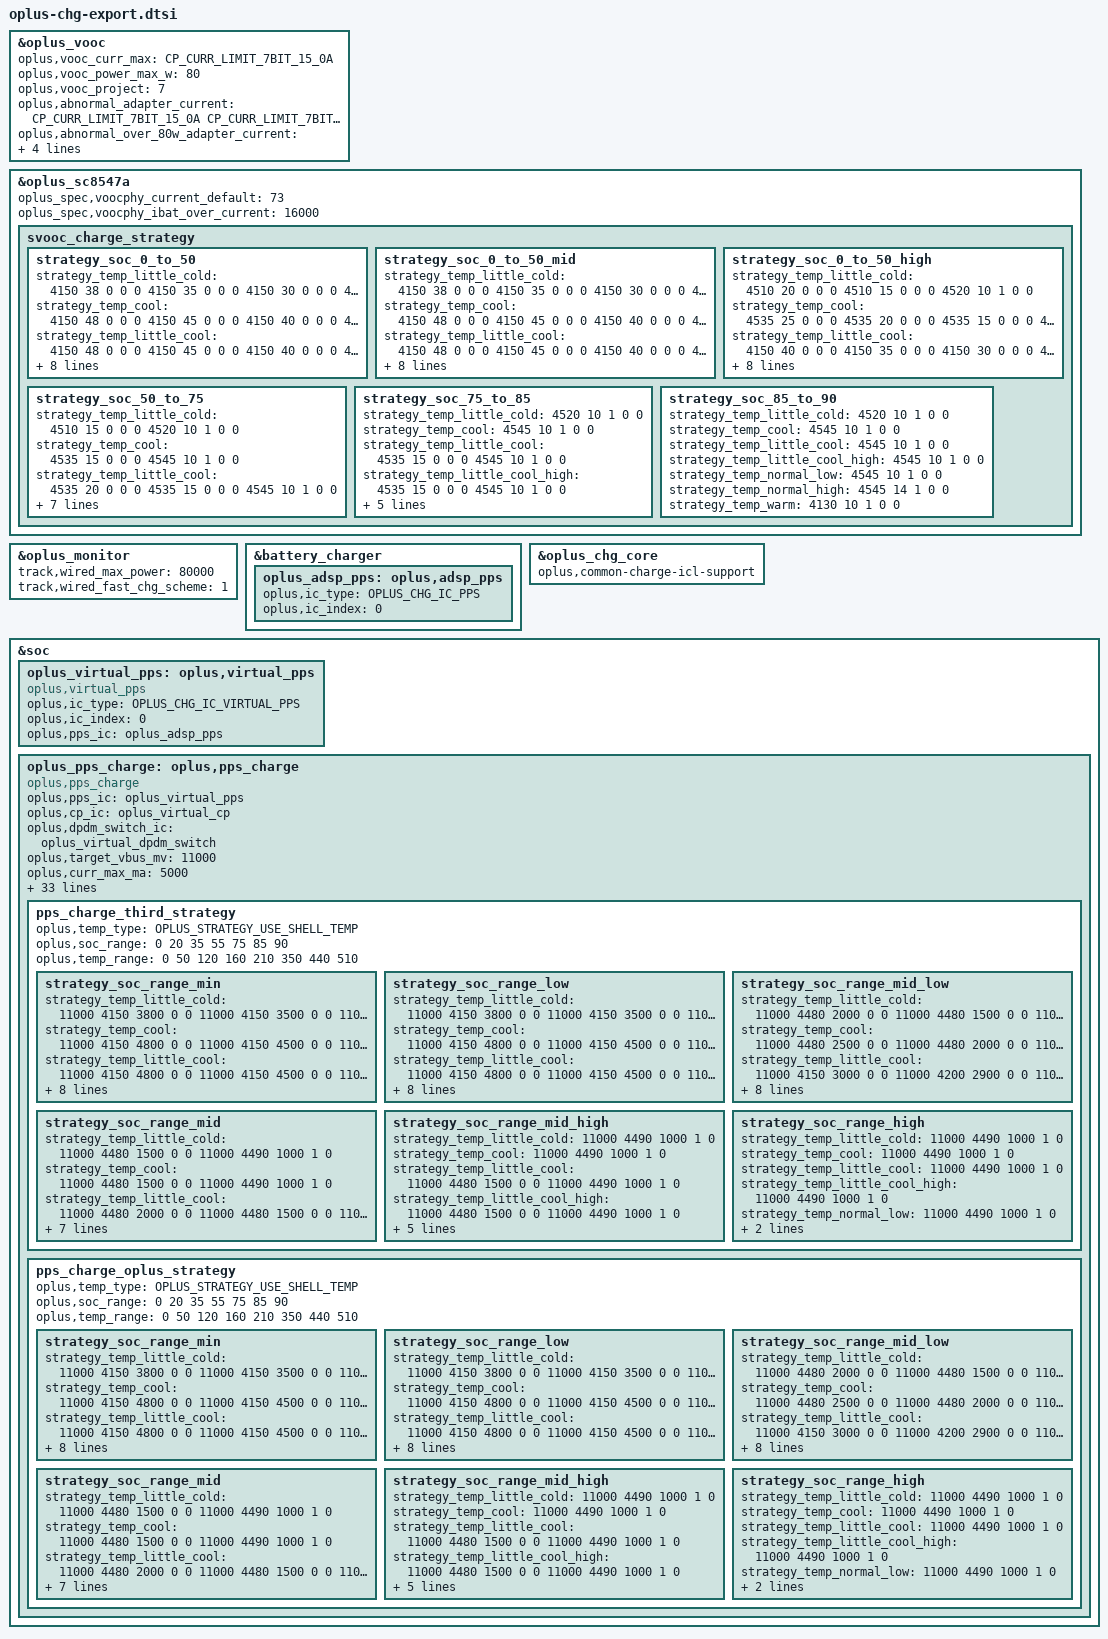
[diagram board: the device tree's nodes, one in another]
/* SVOOC */
&oplus_vooc {
	oplus,vooc_curr_max = <CP_CURR_LIMIT_7BIT_15_0A>;
	oplus,vooc_power_max_w = <80>;
	oplus,vooc_project = <7>;

	oplus,abnormal_adapter_current = <CP_CURR_LIMIT_7BIT_15_0A CP_CURR_LIMIT_7BIT_15_0A
					CP_CURR_LIMIT_7BIT_10_0A CP_CURR_LIMIT_7BIT_10_0A
					CP_CURR_LIMIT_7BIT_8_0A CP_CURR_LIMIT_7BIT_8_0A
					CP_CURR_LIMIT_7BIT_6_0A CP_CURR_LIMIT_7BIT_6_0A
					CP_CURR_LIMIT_7BIT_4_0A CP_CURR_LIMIT_7BIT_4_0A>;

	oplus,abnormal_over_80w_adapter_current = <CP_CURR_LIMIT_7BIT_15_0A CP_CURR_LIMIT_7BIT_15_0A
					CP_CURR_LIMIT_7BIT_14_0A CP_CURR_LIMIT_7BIT_14_0A
					CP_CURR_LIMIT_7BIT_12_0A CP_CURR_LIMIT_7BIT_12_0A
					CP_CURR_LIMIT_7BIT_10_0A CP_CURR_LIMIT_7BIT_10_0A
					CP_CURR_LIMIT_7BIT_8_0A CP_CURR_LIMIT_7BIT_8_0A
					CP_CURR_LIMIT_7BIT_6_0A CP_CURR_LIMIT_7BIT_6_0A
					CP_CURR_LIMIT_7BIT_4_0A CP_CURR_LIMIT_7BIT_4_0A>;

	/* first data is strategy used temp type */
	oplus,general_strategy_name = "cgcl";
	oplus,general_strategy_data = < OPLUS_STRATEGY_USE_SHELL_TEMP
					0   385 CP_CURR_LIMIT_7BIT_15_0A 1 0
					375 395 CP_CURR_LIMIT_7BIT_12_6A 2 0
					385 420 CP_CURR_LIMIT_7BIT_8_0A 3 1
					410 440 CP_CURR_LIMIT_7BIT_6_0A 3 2 >;
};

&oplus_sc8547a {
	oplus_spec,voocphy_current_default = <73>;
	oplus_spec,voocphy_ibat_over_current = <16000>;
	svooc_charge_strategy {
		strategy_soc_0_to_50 { /* 0 ~ 20 */
			strategy_temp_little_cold =	<4150 38 0 0 0
							4150 35 0 0 0
							4150 30 0 0 0
							4510 26 0 0 0
							4510 25 0 0 0
							4510 20 0 0 0
							4510 15 0 0 0
							4520 10 1 0 0>;
			strategy_temp_cool =		<4150 48 0 0 0
							4150 45 0 0 0
							4150 40 0 0 0
							4150 35 0 0 0
							4150 30 0 0 0
							4200 29 0 0 0
							4535 25 0 0 0
							4535 20 0 0 0
							4535 15 0 0 0
							4545 10 1 0 0>;
			strategy_temp_little_cool =	<4150 48 0 0 0
							4150 45 0 0 0
							4150 40 0 0 0
							4150 35 0 0 0
							4150 30 0 0 0
							4200 29 0 0 0
							4535 25 0 0 0
							4535 20 0 0 0
							4535 15 0 0 0
							4545 10 1 0 0>;
			strategy_temp_little_cool_high = <4050 73 0 0 0
							4230 61 0 0 0
							4230 50 0 0 0
							4230 40 0 0 0
							4380 39 0 0 0
							4380 35 0 0 0
							4380 30 0 0 0
							4535 29 0 0 0
							4535 25 0 0 0
							4535 20 0 0 0
							4535 15 0 0 0
							4545 10 1 0 0>;
			strategy_temp_normal_low =	<4050 73 0 0 0
							4230 61 0 0 0
							4230 50 0 0 0
							4230 40 0 0 0
							4380 39 0 0 0
							4380 35 0 0 0
							4380 30 0 0 0
							4535 29 0 0 0
							4535 25 0 0 0
							4535 20 0 0 0
							4535 15 0 0 0
							4545 10 1 0 0>;
			strategy_temp_normal_high =	<4200 61 0 0 0
							4200 60 0 0 0
							4200 50 0 0 0
							4230 48 0 0 0
							4230 45 0 0 0
							4230 40 0 0 0
							4380 39 0 0 0
							4380 35 0 0 0
							4380 30 0 0 0
							4535 29 0 0 0
							4535 25 0 0 0
							4535 20 0 0 0
							4535 15 0 0 0
							4545 14 1 0 0>;
			strategy_temp_warm =		<4120 32 0 0 0
							4120 30 0 0 0
							4120 25 0 0 0
							4120 20 0 0 0
							4120 15 0 0 0
							4130 10 1 0 0>;
		};

		strategy_soc_0_to_50_mid { /* 21 ~ 35 */
			strategy_temp_little_cold =	<4150 38 0 0 0
							4150 35 0 0 0
							4150 30 0 0 0
							4510 26 0 0 0
							4510 25 0 0 0
							4510 20 0 0 0
							4510 15 0 0 0
							4520 10 1 0 0>;
			strategy_temp_cool =		<4150 48 0 0 0
							4150 45 0 0 0
							4150 40 0 0 0
							4150 35 0 0 0
							4150 30 0 0 0
							4200 29 0 0 0
							4535 25 0 0 0
							4535 20 0 0 0
							4535 15 0 0 0
							4545 10 1 0 0>;
			strategy_temp_little_cool =	<4150 48 0 0 0
							4150 45 0 0 0
							4150 40 0 0 0
							4150 35 0 0 0
							4150 30 0 0 0
							4200 29 0 0 0
							4535 25 0 0 0
							4535 20 0 0 0
							4535 15 0 0 0
							4545 10 1 0 0>;
			strategy_temp_little_cool_high = <4050 73 0 0 0
							4230 61 0 0 0
							4230 50 0 0 0
							4230 40 0 0 0
							4380 39 0 0 0
							4380 35 0 0 0
							4380 30 0 0 0
							4535 29 0 0 0
							4535 25 0 0 0
							4535 20 0 0 0
							4535 15 0 0 0
							4545 10 1 0 0>;
			strategy_temp_normal_low =	<4050 73 0 0 0
							4230 61 0 0 0
							4230 50 0 0 0
							4230 40 0 0 0
							4380 39 0 0 0
							4380 35 0 0 0
							4380 30 0 0 0
							4535 29 0 0 0
							4535 25 0 0 0
							4535 20 0 0 0
							4535 15 0 0 0
							4545 10 1 0 0>;
			strategy_temp_normal_high =	<4200 61 0 0 0
							4200 60 0 0 0
							4200 50 0 0 0
							4230 48 0 0 0
							4230 45 0 0 0
							4230 40 0 0 0
							4380 39 0 0 0
							4380 35 0 0 0
							4380 30 0 0 0
							4535 29 0 0 0
							4535 25 0 0 0
							4535 20 0 0 0
							4535 15 0 0 0
							4545 14 1 0 0>;
			strategy_temp_warm =		<4120 32 0 0 0
							4120 30 0 0 0
							4120 25 0 0 0
							4120 20 0 0 0
							4120 15 0 0 0
							4130 10 1 0 0>;
		};

		strategy_soc_0_to_50_high { /* 36 ~ 55 */
			strategy_temp_little_cold =	<4510 20 0 0 0
							4510 15 0 0 0
							4520 10 1 0 0>;
			strategy_temp_cool =		<4535 25 0 0 0
							4535 20 0 0 0
							4535 15 0 0 0
							4545 10 1 0 0>;
			strategy_temp_little_cool =	<4150 40 0 0 0
							4150 35 0 0 0
							4150 30 0 0 0
							4200 29 0 0 0
							4535 25 0 0 0
							4535 20 0 0 0
							4535 15 0 0 0
							4545 10 1 0 0>;
			strategy_temp_little_cool_high = <4230 40 0 0 0
							4380 39 0 0 0
							4380 35 0 0 0
							4380 30 0 0 0
							4535 29 0 0 0
							4535 25 0 0 0
							4535 20 0 0 0
							4535 15 0 0 0
							4545 10 1 0 0>;
			strategy_temp_normal_low =	<4230 61 0 0 0
							4230 50 0 0 0
							4230 40 0 0 0
							4380 39 0 0 0
							4380 35 0 0 0
							4380 30 0 0 0
							4535 29 0 0 0
							4535 25 0 0 0
							4535 20 0 0 0
							4535 15 0 0 0
							4545 10 1 0 0>;
			strategy_temp_normal_high =	<4200 61 0 0 0
							4200 60 0 0 0
							4200 50 0 0 0
							4230 48 0 0 0
							4230 45 0 0 0
							4230 40 0 0 0
							4380 39 0 0 0
							4380 35 0 0 0
							4380 30 0 0 0
							4535 29 0 0 0
							4535 25 0 0 0
							4535 20 0 0 0
							4535 15 0 0 0
							4545 14 1 0 0>;
			strategy_temp_warm =		<4120 32 0 0 0
							4120 30 0 0 0
							4120 25 0 0 0
							4120 20 0 0 0
							4120 15 0 0 0
							4130 10 1 0 0>;
		};

		strategy_soc_50_to_75 { /* 56 ~ 75 */
			strategy_temp_little_cold =	<4510 15 0 0 0
							4520 10 1 0 0>;
			strategy_temp_cool =		<4535 15 0 0 0
							4545 10 1 0 0>;
			strategy_temp_little_cool =	<4535 20 0 0 0
							4535 15 0 0 0
							4545 10 1 0 0>;
			strategy_temp_little_cool_high = <4535 20 0 0 0
							4535 15 0 0 0
							4545 10 1 0 0>;
			strategy_temp_normal_low =	<4535 25 0 0 0
							4535 20 0 0 0
							4535 15 0 0 0
							4545 10 1 0 0>;
			strategy_temp_normal_high =	<4380 30 0 0 0
							4535 29 0 0 0
							4535 25 0 0 0
							4535 20 0 0 0
							4535 15 0 0 0
							4545 14 1 0 0>;
			strategy_temp_warm =		<4130 10 1 0 0>;
		};

		strategy_soc_75_to_85 { /* 76 ~ 85 */
			strategy_temp_little_cold =	<4520 10 1 0 0>;
			strategy_temp_cool =		<4545 10 1 0 0>;
			strategy_temp_little_cool =	<4535 15 0 0 0
							4545 10 1 0 0>;
			strategy_temp_little_cool_high = <4535 15 0 0 0
							4545 10 1 0 0>;
			strategy_temp_normal_low =	<4535 15 0 0 0
							4545 10 1 0 0>;
			strategy_temp_normal_high =	<4535 20 0 0 0
							4535 15 0 0 0
							4545 14 1 0 0>;
			strategy_temp_warm =		<4130 10 1 0 0>;
		};

		strategy_soc_85_to_90 { /* 86 ~ 90 */
			strategy_temp_little_cold =	<4520 10 1 0 0>;
			strategy_temp_cool =		<4545 10 1 0 0>;
			strategy_temp_little_cool =	<4545 10 1 0 0>;
			strategy_temp_little_cool_high = <4545 10 1 0 0>;
			strategy_temp_normal_low =	<4545 10 1 0 0>;
			strategy_temp_normal_high =	<4545 14 1 0 0>;
			strategy_temp_warm =		<4130 10 1 0 0>;
		};
	};
};
&oplus_monitor {
	track,wired_max_power = <80000>;
	track,wired_fast_chg_scheme = <1>;
};

/* PPS */
&battery_charger {
	oplus_adsp_pps: oplus,adsp_pps {
		oplus,ic_type = <OPLUS_CHG_IC_PPS>;
		oplus,ic_index = <0>;
	};
};

&oplus_chg_core {
	oplus,common-charge-icl-support;
};

&soc {
	oplus_virtual_pps: oplus,virtual_pps {
		compatible = "oplus,virtual_pps";

		oplus,ic_type = <OPLUS_CHG_IC_VIRTUAL_PPS>;
		oplus,ic_index = <0>;
		oplus,pps_ic = <&oplus_adsp_pps>;
	};

	oplus_pps_charge: oplus,pps_charge {
		compatible = "oplus,pps_charge";
		oplus,pps_ic = <&oplus_virtual_pps>;
		oplus,cp_ic = <&oplus_virtual_cp>;
		oplus,dpdm_switch_ic = <&oplus_virtual_dpdm_switch>;

		oplus,target_vbus_mv = <11000>;
		oplus,curr_max_ma = <5000>;
		oplus,curr_max_ma_percent = <2000 /* 75% ibus */
					     1000 /* 85% ibus */>;
		oplus,lift_vbus_use_cpvout;
		oplus,process_close_cp_item;

		oplus,pps_warm_allow_vol = <4000>;
		oplus,pps_warm_allow_soc = <55>;
		oplus,pps_strategy_normal_current = <5000>;
		oplus,pps_over_high_or_low_current = <3000>;
		oplus,pps_timeout_third = <30188>;
		oplus,pps_timeout_oplus = <30188>;
		oplus,pps_ibat_over_third = <55 11400
					     33 7400>;
		oplus,pps_ibat_over_oplus = <55 11400
					     33 7400>;
		oplus,pps_full_cool_sw_vbat = <4490>;
		oplus,pps_full_normal_sw_vbat = <4490>;
		oplus,pps_full_normal_hw_vbat = <4540>;
		oplus,pps_full_ffc_vbat = <4485>;
		oplus,pps_full_warm_vbat = <4130>;
		oplus,pps_full_cool_sw_vbat_third = <4490>;
		oplus,pps_full_normal_sw_vbat_third= <4490>;
		oplus,pps_full_normal_hw_vbat_third = <4540>;
		oplus,pps_current_change_timeout = <100>;
		oplus,pps_strategy_batt_high_temp = <410 420 430 400 410 420>;
		oplus,pps_strategy_high_current = <5000 5000 3000 5000 5000 5000>;
		oplus,pps_little_cool_high_temp = <210>;
		oplus,curve_strategy_name = "pps_ufcs_curve_v2";
		oplus,pps_charge_strategy_soc = <0 20 35 55 75 85 85>;
		oplus,pps_charge_strategy_temp = <0 50 120 160 350 440 510>;
		oplus,temperature_strategy_name = "cgcl";
		oplus,temperature_strategy_data = <OPLUS_STRATEGY_USE_SHELL_TEMP
						0   385 7300 1 0
						375 405 5000 2 0
						395 420 4000 3 1
						410 430 3500 4 2
						420 440 2000 4 3>;
		pps_charge_third_strategy {
			oplus,temp_type = <OPLUS_STRATEGY_USE_SHELL_TEMP>;
			oplus,soc_range = <0 20 35 55 75 85 90>;
			oplus,temp_range = <0 50 120 160 210 350 440 510>;

			strategy_soc_range_min {
				strategy_temp_little_cold =	<11000 4150 3800 0 0
								11000 4150 3500 0 0
								11000 4150 3000 0 0
								11000 4480 2600 0 0
								11000 4480 2500 0 0
								11000 4480 2000 0 0
								11000 4480 1500 0 0
								11000 4490 1000 1 0>;
				strategy_temp_cool =		<11000 4150 4800 0 0
								11000 4150 4500 0 0
								11000 4150 4000 0 0
								11000 4150 3500 0 0
								11000 4150 3000 0 0
								11000 4200 2900 0 0
								11000 4480 2500 0 0
								11000 4480 2000 0 0
								11000 4480 1500 0 0
								11000 4490 1000 1 0>;
				strategy_temp_little_cool =	<11000 4150 4800 0 0
								11000 4150 4500 0 0
								11000 4150 4000 0 0
								11000 4150 3500 0 0
								11000 4150 3000 0 0
								11000 4200 2900 0 0
								11000 4480 2500 0 0
								11000 4480 2000 0 0
								11000 4480 1500 0 0
								11000 4490 1000 1 0>;
				strategy_temp_little_cool_high = <11000 4230 5000 0 0
								11000 4230 4000 0 0
								11000 4380 3900 0 0
								11000 4380 3500 0 0
								11000 4380 3000 0 0
								11000 4480 2900 0 0
								11000 4480 2500 0 0
								11000 4480 2000 0 0
								11000 4480 1500 0 0
								11000 4490 1000 1 0>;
				strategy_temp_normal_low =	<11000 4230 5000 0 0
								11000 4230 4000 0 0
								11000 4380 3900 0 0
								11000 4380 3500 0 0
								11000 4380 3000 0 0
								11000 4480 2900 0 0
								11000 4480 2500 0 0
								11000 4480 2000 0 0
								11000 4480 1500 0 0
								11000 4490 1000 1 0>;
				strategy_temp_normal_high =	<11000 4200 5000 0 0
								11000 4230 4800 0 0
								11000 4230 4000 0 0
								11000 4380 3900 0 0
								11000 4380 3500 0 0
								11000 4380 3000 0 0
								11000 4460 2900 0 0
								11000 4460 2500 0 0
								11000 4460 2000 0 0
								11000 4460 1500 0 0
								11000 4470 1000 1 0>;
				strategy_temp_warm =		<11000 4120 3200 0 0
								11000 4120 3000 0 0
								11000 4120 2500 0 0
								11000 4120 2000 0 0
								11000 4120 1500 0 0
								11000 4130 1000 1 0>;
			};
			strategy_soc_range_low {
				strategy_temp_little_cold =	<11000 4150 3800 0 0
								11000 4150 3500 0 0
								11000 4150 3000 0 0
								11000 4480 2600 0 0
								11000 4480 2500 0 0
								11000 4480 2000 0 0
								11000 4480 1500 0 0
								11000 4490 1000 1 0>;
				strategy_temp_cool =		<11000 4150 4800 0 0
								11000 4150 4500 0 0
								11000 4150 4000 0 0
								11000 4150 3500 0 0
								11000 4150 3000 0 0
								11000 4200 2900 0 0
								11000 4480 2500 0 0
								11000 4480 2000 0 0
								11000 4480 1500 0 0
								11000 4490 1000 1 0>;
				strategy_temp_little_cool =	<11000 4150 4800 0 0
								11000 4150 4500 0 0
								11000 4150 4000 0 0
								11000 4150 3500 0 0
								11000 4150 3000 0 0
								11000 4200 2900 0 0
								11000 4480 2500 0 0
								11000 4480 2000 0 0
								11000 4480 1500 0 0
								11000 4490 1000 1 0>;
				strategy_temp_little_cool_high = <11000 4230 5000 0 0
								11000 4230 4000 0 0
								11000 4380 3900 0 0
								11000 4380 3500 0 0
								11000 4380 3000 0 0
								11000 4480 2900 0 0
								11000 4480 2500 0 0
								11000 4480 2000 0 0
								11000 4480 1500 0 0
								11000 4490 1000 1 0>;
				strategy_temp_normal_low =	<11000 4230 5000 0 0
								11000 4230 4000 0 0
								11000 4380 3900 0 0
								11000 4380 3500 0 0
								11000 4380 3000 0 0
								11000 4480 2900 0 0
								11000 4480 2500 0 0
								11000 4480 2000 0 0
								11000 4480 1500 0 0
								11000 4490 1000 1 0>;
				strategy_temp_normal_high =	<11000 4200 5000 0 0
								11000 4230 4800 0 0
								11000 4230 4000 0 0
								11000 4380 3900 0 0
								11000 4380 3500 0 0
								11000 4380 3000 0 0
								11000 4460 2900 0 0
								11000 4460 2500 0 0
								11000 4460 2000 0 0
								11000 4460 1500 0 0
								11000 4470 1000 1 0>;
				strategy_temp_warm =		<11000 4120 3200 0 0
								11000 4120 3000 0 0
								11000 4120 2500 0 0
								11000 4120 2000 0 0
								11000 4120 1500 0 0
								11000 4130 1000 1 0>;
			};
			strategy_soc_range_mid_low {
				strategy_temp_little_cold =	<11000 4480 2000 0 0
								11000 4480 1500 0 0
								11000 4490 1000 1 0>;
				strategy_temp_cool =		<11000 4480 2500 0 0
								11000 4480 2000 0 0
								11000 4480 1500 0 0
								11000 4490 1000 1 0>;
				strategy_temp_little_cool =	<11000 4150 3000 0 0
								11000 4200 2900 0 0
								11000 4480 2500 0 0
								11000 4480 2000 0 0
								11000 4480 1500 0 0
								11000 4490 1000 1 0>;
				strategy_temp_little_cool_high = <11000 4380 3000 0 0
								11000 4480 2900 0 0
								11000 4480 2500 0 0
								11000 4480 2000 0 0
								11000 4480 1500 0 0
								11000 4490 1000 1 0>;
				strategy_temp_normal_low =	<11000 4230 5000 0 0
								11000 4230 4000 0 0
								11000 4380 3900 0 0
								11000 4380 3500 0 0
								11000 4380 3000 0 0
								11000 4480 2900 0 0
								11000 4480 2500 0 0
								11000 4480 2000 0 0
								11000 4480 1500 0 0
								11000 4490 1000 1 0>;
				strategy_temp_normal_high =	<11000 4200 5000 0 0
								11000 4230 4800 0 0
								11000 4230 4000 0 0
								11000 4380 3900 0 0
								11000 4380 3500 0 0
								11000 4380 3000 0 0
								11000 4460 2900 0 0
								11000 4460 2500 0 0
								11000 4460 2000 0 0
								11000 4460 1500 0 0
								11000 4470 1000 1 0>;
				strategy_temp_warm =		<11000 4120 3200 0 0
								11000 4120 3000 0 0
								11000 4120 2500 0 0
								11000 4120 2000 0 0
								11000 4120 1500 0 0
								11000 4130 1000 1 0>;
			};
			strategy_soc_range_mid {
				strategy_temp_little_cold =	<11000 4480 1500 0 0
								11000 4490 1000 1 0>;
				strategy_temp_cool =		<11000 4480 1500 0 0
								11000 4490 1000 1 0>;
				strategy_temp_little_cool =	<11000 4480 2000 0 0
								11000 4480 1500 0 0
								11000 4490 1000 1 0>;
				strategy_temp_little_cool_high = <11000 4480 2000 0 0
								11000 4480 1500 0 0
								11000 4490 1000 1 0>;
				strategy_temp_normal_low =	<11000 4480 2000 0 0
								11000 4480 1500 0 0
								11000 4490 1000 1 0>;
				strategy_temp_normal_high =	<11000 4460 2500 0 0
								11000 4460 2000 0 0
								11000 4460 1500 0 0
								11000 4470 1000 1 0>;
				strategy_temp_warm =		<11000 4130 1000 1 0>;
			};
			strategy_soc_range_mid_high {
				strategy_temp_little_cold =	<11000 4490 1000 1 0>;
				strategy_temp_cool =		<11000 4490 1000 1 0>;
				strategy_temp_little_cool =	<11000 4480 1500 0 0
								11000 4490 1000 1 0>;
				strategy_temp_little_cool_high = <11000 4480 1500 0 0
								11000 4490 1000 1 0>;
				strategy_temp_normal_low =	<11000 4480 1500 0 0
								11000 4490 1000 1 0>;
				strategy_temp_normal_high =	<11000 4460 1500 0 0
								11000 4470 1000 1 0>;
				strategy_temp_warm =		<11000 4130 1000 1 0>;
			};
			strategy_soc_range_high {
				strategy_temp_little_cold =	<11000 4490 1000 1 0>;
				strategy_temp_cool =		<11000 4490 1000 1 0>;
				strategy_temp_little_cool =	<11000 4490 1000 1 0>;
				strategy_temp_little_cool_high = <11000 4490 1000 1 0>;
				strategy_temp_normal_low =	<11000 4490 1000 1 0>;
				strategy_temp_normal_high =	<11000 4470 1000 1 0>;
				strategy_temp_warm =		<11000 4130 1000 1 0>;
			};
		};

		pps_charge_oplus_strategy {
			oplus,temp_type = <OPLUS_STRATEGY_USE_SHELL_TEMP>;
			oplus,soc_range = <0 20 35 55 75 85 90>;
			oplus,temp_range = <0 50 120 160 210 350 440 510>;

			strategy_soc_range_min {
				strategy_temp_little_cold =	<11000 4150 3800 0 0
								11000 4150 3500 0 0
								11000 4150 3000 0 0
								11000 4480 2600 0 0
								11000 4480 2500 0 0
								11000 4480 2000 0 0
								11000 4480 1500 0 0
								11000 4490 1000 1 0>;
				strategy_temp_cool =		<11000 4150 4800 0 0
								11000 4150 4500 0 0
								11000 4150 4000 0 0
								11000 4150 3500 0 0
								11000 4150 3000 0 0
								11000 4200 2900 0 0
								11000 4480 2500 0 0
								11000 4480 2000 0 0
								11000 4480 1500 0 0
								11000 4490 1000 1 0>;
				strategy_temp_little_cool =	<11000 4150 4800 0 0
								11000 4150 4500 0 0
								11000 4150 4000 0 0
								11000 4150 3500 0 0
								11000 4150 3000 0 0
								11000 4200 2900 0 0
								11000 4480 2500 0 0
								11000 4480 2000 0 0
								11000 4480 1500 0 0
								11000 4490 1000 1 0>;
				strategy_temp_little_cool_high = <11000 4230 5000 0 0
								11000 4230 4000 0 0
								11000 4380 3900 0 0
								11000 4380 3500 0 0
								11000 4380 3000 0 0
								11000 4480 2900 0 0
								11000 4480 2500 0 0
								11000 4480 2000 0 0
								11000 4480 1500 0 0
								11000 4490 1000 1 0>;
				strategy_temp_normal_low =	<11000 4230 5000 0 0
								11000 4230 4000 0 0
								11000 4380 3900 0 0
								11000 4380 3500 0 0
								11000 4380 3000 0 0
								11000 4480 2900 0 0
								11000 4480 2500 0 0
								11000 4480 2000 0 0
								11000 4480 1500 0 0
								11000 4490 1000 1 0>;
				strategy_temp_normal_high =	<11000 4200 5000 0 0
								11000 4230 4800 0 0
								11000 4230 4000 0 0
								11000 4380 3900 0 0
								11000 4380 3500 0 0
								11000 4380 3000 0 0
								11000 4460 2900 0 0
								11000 4460 2500 0 0
								11000 4460 2000 0 0
								11000 4460 1500 0 0
								11000 4470 1000 1 0>;
				strategy_temp_warm =		<11000 4120 3200 0 0
								11000 4120 3000 0 0
								11000 4120 2500 0 0
								11000 4120 2000 0 0
								11000 4120 1500 0 0
								11000 4130 1000 1 0>;
			};
			strategy_soc_range_low {
				strategy_temp_little_cold =	<11000 4150 3800 0 0
								11000 4150 3500 0 0
								11000 4150 3000 0 0
								11000 4480 2600 0 0
								11000 4480 2500 0 0
								11000 4480 2000 0 0
								11000 4480 1500 0 0
								11000 4490 1000 1 0>;
				strategy_temp_cool =		<11000 4150 4800 0 0
								11000 4150 4500 0 0
								11000 4150 4000 0 0
								11000 4150 3500 0 0
								11000 4150 3000 0 0
								11000 4200 2900 0 0
								11000 4480 2500 0 0
								11000 4480 2000 0 0
								11000 4480 1500 0 0
								11000 4490 1000 1 0>;
				strategy_temp_little_cool =	<11000 4150 4800 0 0
								11000 4150 4500 0 0
								11000 4150 4000 0 0
								11000 4150 3500 0 0
								11000 4150 3000 0 0
								11000 4200 2900 0 0
								11000 4480 2500 0 0
								11000 4480 2000 0 0
								11000 4480 1500 0 0
								11000 4490 1000 1 0>;
				strategy_temp_little_cool_high = <11000 4230 5000 0 0
								11000 4230 4000 0 0
								11000 4380 3900 0 0
								11000 4380 3500 0 0
								11000 4380 3000 0 0
								11000 4480 2900 0 0
								11000 4480 2500 0 0
								11000 4480 2000 0 0
								11000 4480 1500 0 0
								11000 4490 1000 1 0>;
				strategy_temp_normal_low =	<11000 4230 5000 0 0
								11000 4230 4000 0 0
								11000 4380 3900 0 0
								11000 4380 3500 0 0
								11000 4380 3000 0 0
								11000 4480 2900 0 0
								11000 4480 2500 0 0
								11000 4480 2000 0 0
								11000 4480 1500 0 0
								11000 4490 1000 1 0>;
				strategy_temp_normal_high =	<11000 4200 5000 0 0
								11000 4230 4800 0 0
								11000 4230 4000 0 0
								11000 4380 3900 0 0
								11000 4380 3500 0 0
								11000 4380 3000 0 0
								11000 4460 2900 0 0
								11000 4460 2500 0 0
								11000 4460 2000 0 0
								11000 4460 1500 0 0
								11000 4470 1000 1 0>;
				strategy_temp_warm =		<11000 4120 3200 0 0
								11000 4120 3000 0 0
								11000 4120 2500 0 0
								11000 4120 2000 0 0
								11000 4120 1500 0 0
								11000 4130 1000 1 0>;
			};
			strategy_soc_range_mid_low {
				strategy_temp_little_cold =	<11000 4480 2000 0 0
								11000 4480 1500 0 0
								11000 4490 1000 1 0>;
				strategy_temp_cool =		<11000 4480 2500 0 0
								11000 4480 2000 0 0
								11000 4480 1500 0 0
								11000 4490 1000 1 0>;
				strategy_temp_little_cool =	<11000 4150 3000 0 0
								11000 4200 2900 0 0
								11000 4480 2500 0 0
								11000 4480 2000 0 0
								11000 4480 1500 0 0
								11000 4490 1000 1 0>;
				strategy_temp_little_cool_high = <11000 4380 3000 0 0
								11000 4480 2900 0 0
								11000 4480 2500 0 0
								11000 4480 2000 0 0
								11000 4480 1500 0 0
								11000 4490 1000 1 0>;
				strategy_temp_normal_low =	<11000 4230 5000 0 0
								11000 4230 4000 0 0
								11000 4380 3900 0 0
								11000 4380 3500 0 0
								11000 4380 3000 0 0
								11000 4480 2900 0 0
								11000 4480 2500 0 0
								11000 4480 2000 0 0
								11000 4480 1500 0 0
								11000 4490 1000 1 0>;
				strategy_temp_normal_high =	<11000 4200 5000 0 0
								11000 4230 4800 0 0
								11000 4230 4000 0 0
								11000 4380 3900 0 0
								11000 4380 3500 0 0
								11000 4380 3000 0 0
								11000 4460 2900 0 0
								11000 4460 2500 0 0
								11000 4460 2000 0 0
								11000 4460 1500 0 0
								11000 4470 1000 1 0>;
				strategy_temp_warm =		<11000 4120 3200 0 0
								11000 4120 3000 0 0
								11000 4120 2500 0 0
								11000 4120 2000 0 0
								11000 4120 1500 0 0
								11000 4130 1000 1 0>;
			};
			strategy_soc_range_mid {
				strategy_temp_little_cold =	<11000 4480 1500 0 0
								11000 4490 1000 1 0>;
				strategy_temp_cool =		<11000 4480 1500 0 0
								11000 4490 1000 1 0>;
				strategy_temp_little_cool =	<11000 4480 2000 0 0
								11000 4480 1500 0 0
								11000 4490 1000 1 0>;
				strategy_temp_little_cool_high = <11000 4480 2000 0 0
								11000 4480 1500 0 0
								11000 4490 1000 1 0>;
				strategy_temp_normal_low =	<11000 4480 2000 0 0
								11000 4480 1500 0 0
								11000 4490 1000 1 0>;
				strategy_temp_normal_high =	<11000 4460 2500 0 0
								11000 4460 2000 0 0
								11000 4460 1500 0 0
								11000 4470 1000 1 0>;
				strategy_temp_warm =		<11000 4130 1000 1 0>;
			};
			strategy_soc_range_mid_high {
				strategy_temp_little_cold =	<11000 4490 1000 1 0>;
				strategy_temp_cool =		<11000 4490 1000 1 0>;
				strategy_temp_little_cool =	<11000 4480 1500 0 0
								11000 4490 1000 1 0>;
				strategy_temp_little_cool_high = <11000 4480 1500 0 0
								11000 4490 1000 1 0>;
				strategy_temp_normal_low =	<11000 4480 1500 0 0
								11000 4490 1000 1 0>;
				strategy_temp_normal_high =	<11000 4460 1500 0 0
								11000 4470 1000 1 0>;
				strategy_temp_warm =		<11000 4130 1000 1 0>;
			};
			strategy_soc_range_high {
				strategy_temp_little_cold =	<11000 4490 1000 1 0>;
				strategy_temp_cool =		<11000 4490 1000 1 0>;
				strategy_temp_little_cool =	<11000 4490 1000 1 0>;
				strategy_temp_little_cool_high = <11000 4490 1000 1 0>;
				strategy_temp_normal_low =	<11000 4490 1000 1 0>;
				strategy_temp_normal_high =	<11000 4470 1000 1 0>;
				strategy_temp_warm =		<11000 4130 1000 1 0>;
			};
		};
	};
};
